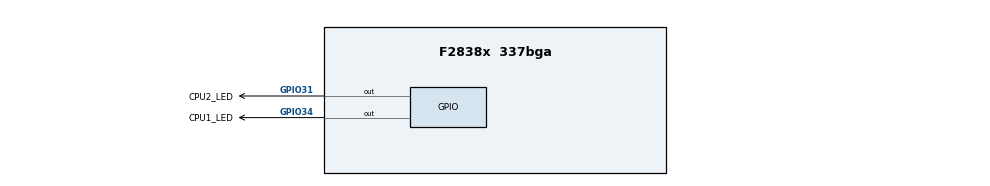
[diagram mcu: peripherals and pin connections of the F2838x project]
/**
 * @cliArgs --device "F2838x" --package "337bga" --part "F2838x_337bga" --context "CPU1" --product "C2000WARE@4.03.00.00"
 * @versions {"tool":"1.15.999+71"}
 */

/**
 * Import the modules used in this configuration.
 */
const cputimer  = scripting.addModule("/driverlib/cputimer.js", {}, false);
const cputimer1 = cputimer.addInstance();
const gpio      = scripting.addModule("/driverlib/gpio.js", {}, false);
const gpio1     = gpio.addInstance();
const gpio2     = gpio.addInstance();
const ipc       = scripting.addModule("/driverlib/ipc.js");
const memcfg    = scripting.addModule("/driverlib/memcfg.js");
const CMD       = scripting.addModule("/utilities/cmd_tool/cmd_syscfg/source/CMD");
const CMD1      = CMD.addInstance();

/**
 * Write custom configuration values to the imported modules.
 */
cputimer1.$name       = "myCPUTIMER0";
cputimer1.timerPeriod = 4294967295;

gpio1.$name           = "CPU1_LED";
gpio1.direction       = "GPIO_DIR_MODE_OUT";
gpio1.gpioPin.$assign = "GPIO34";

gpio2.$name           = "CPU2_LED";
gpio2.direction       = "GPIO_DIR_MODE_OUT";
gpio2.controllerCore  = "GPIO_CORE_CPU2";
gpio2.gpioPin.$assign = "GPIO31";

memcfg.config_MEMCFG_SECT_GS0  = "MEMCFG_GSRAMCONTROLLER_CPU2";
memcfg.config_MEMCFG_SECT_GS14 = "MEMCFG_GSRAMCONTROLLER_CPU2";

CMD.activateCMD = true;

CMD1.$name                               = "CMD0";
CMD1.sectionMemory_text                  = ["FLASH1","FLASH2","FLASH3","FLASH4"];
CMD1.sectionAlignEnable_text             = true;
CMD1.sectionMemory_ramfunc               = ["FLASH3"];
CMD1.sectionRunFromDifferentAddr_ramfunc = true;
CMD1.sectionRun_ramfunc                  = ["RAMLS0"];
CMD1.sectionAlignEnable_ramfunc          = true;
CMD1.sectionMemory_ovly                  = ["FLASH1"];
CMD1.sectionAlignEnable_ovly             = true;
CMD1.sectionMemory_cinit                 = ["FLASH4"];
CMD1.sectionAlignEnable_cinit            = true;
CMD1.sectionMemory_stack                 = ["RAMM1"];
CMD1.sectionMemory_init_array            = ["FLASH1"];
CMD1.sectionAlignEnable_init_array       = true;
CMD1.sectionMemory_bss                   = ["RAMLS5"];
CMD1.sectionMemory_const                 = ["FLASH5"];
CMD1.sectionAlignEnable_const            = true;
CMD1.sectionMemory_data                  = ["RAMLS5"];
CMD1.sectionMemory_switch                = ["FLASH1"];
CMD1.sectionAlignEnable_switch           = true;
CMD1.sectionMemory_sysmem                = ["RAMLS5"];
CMD1.sectionAlignEnable_binit            = true;
CMD1.sectionMemory_binit                 = ["FLASH0"];
CMD1.userSection.create(3);
CMD1.userSection[0].$name                = "SHARERAMGS0";
CMD1.userSection[0].sectionName          = "SHARERAMGS0";
CMD1.userSection[0].sectionMemory        = ["RAMGS0"];
CMD1.userSection[1].$name                = "SHARERAMGS1";
CMD1.userSection[1].sectionName          = "SHARERAMGS1";
CMD1.userSection[1].sectionMemory        = ["RAMGS1"];
CMD1.userSection[2].$name                = "isrfunc";
CMD1.userSection[2].sectionName          = "isrfunc";
CMD1.userSection[2].sectionMemory        = ["RAMGS15"];
scripting.suppress("RAMGS0 is not configured to be owned by CPU1 in @@@.+?@@@\\. CPU1 will only have read access to this memory\\.", CMD1.userSection[0], "sectionMemory");
